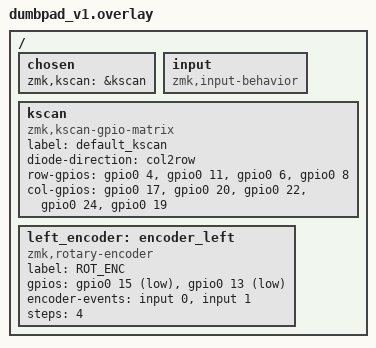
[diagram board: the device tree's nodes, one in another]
#include <dt-bindings/zmk/keys.h>
#include <dt-bindings/zmk/matrix_transform.h>

/ {
    chosen {
        zmk,kscan = &kscan;
    };
    
    input: input {
        compatible = "zmk,input-behavior";
    };

    kscan: kscan {
        compatible = "zmk,kscan-gpio-matrix";
        label = "default_kscan";
        diode-direction = "col2row";

        row-gpios = <&gpio0 4 (GPIO_ACTIVE_HIGH | GPIO_PULL_DOWN)>,   /* Row 0 */
                    <&gpio0 11 (GPIO_ACTIVE_HIGH | GPIO_PULL_DOWN)>,  /* Row 1 */
                    <&gpio0 6 (GPIO_ACTIVE_HIGH | GPIO_PULL_DOWN)>,   /* Row 2 */
                    <&gpio0 8 (GPIO_ACTIVE_HIGH | GPIO_PULL_DOWN)>;   /* Row 3 */

        col-gpios = <&gpio0 17 GPIO_ACTIVE_HIGH>,  /* Col 0 */
                    <&gpio0 20 GPIO_ACTIVE_HIGH>,  /* Col 1 */
                    <&gpio0 22 GPIO_ACTIVE_HIGH>,  /* Col 2 */
                    <&gpio0 24 GPIO_ACTIVE_HIGH>,  /* Col 3 */
                    <&gpio0 19  GPIO_ACTIVE_HIGH>;  /* Col 4 */
    };

    left_encoder: encoder_left {
        compatible = "zmk,rotary-encoder";
        label = "ROT_ENC";
        gpios = <&gpio0 15 GPIO_ACTIVE_LOW>, <&gpio0 13 GPIO_ACTIVE_LOW>; // example: B2 and D4
        encoder-events = <&input 0 &input 1>;
        steps = <4>;
        #sensor-binding-cells = <2>;

    };



};
